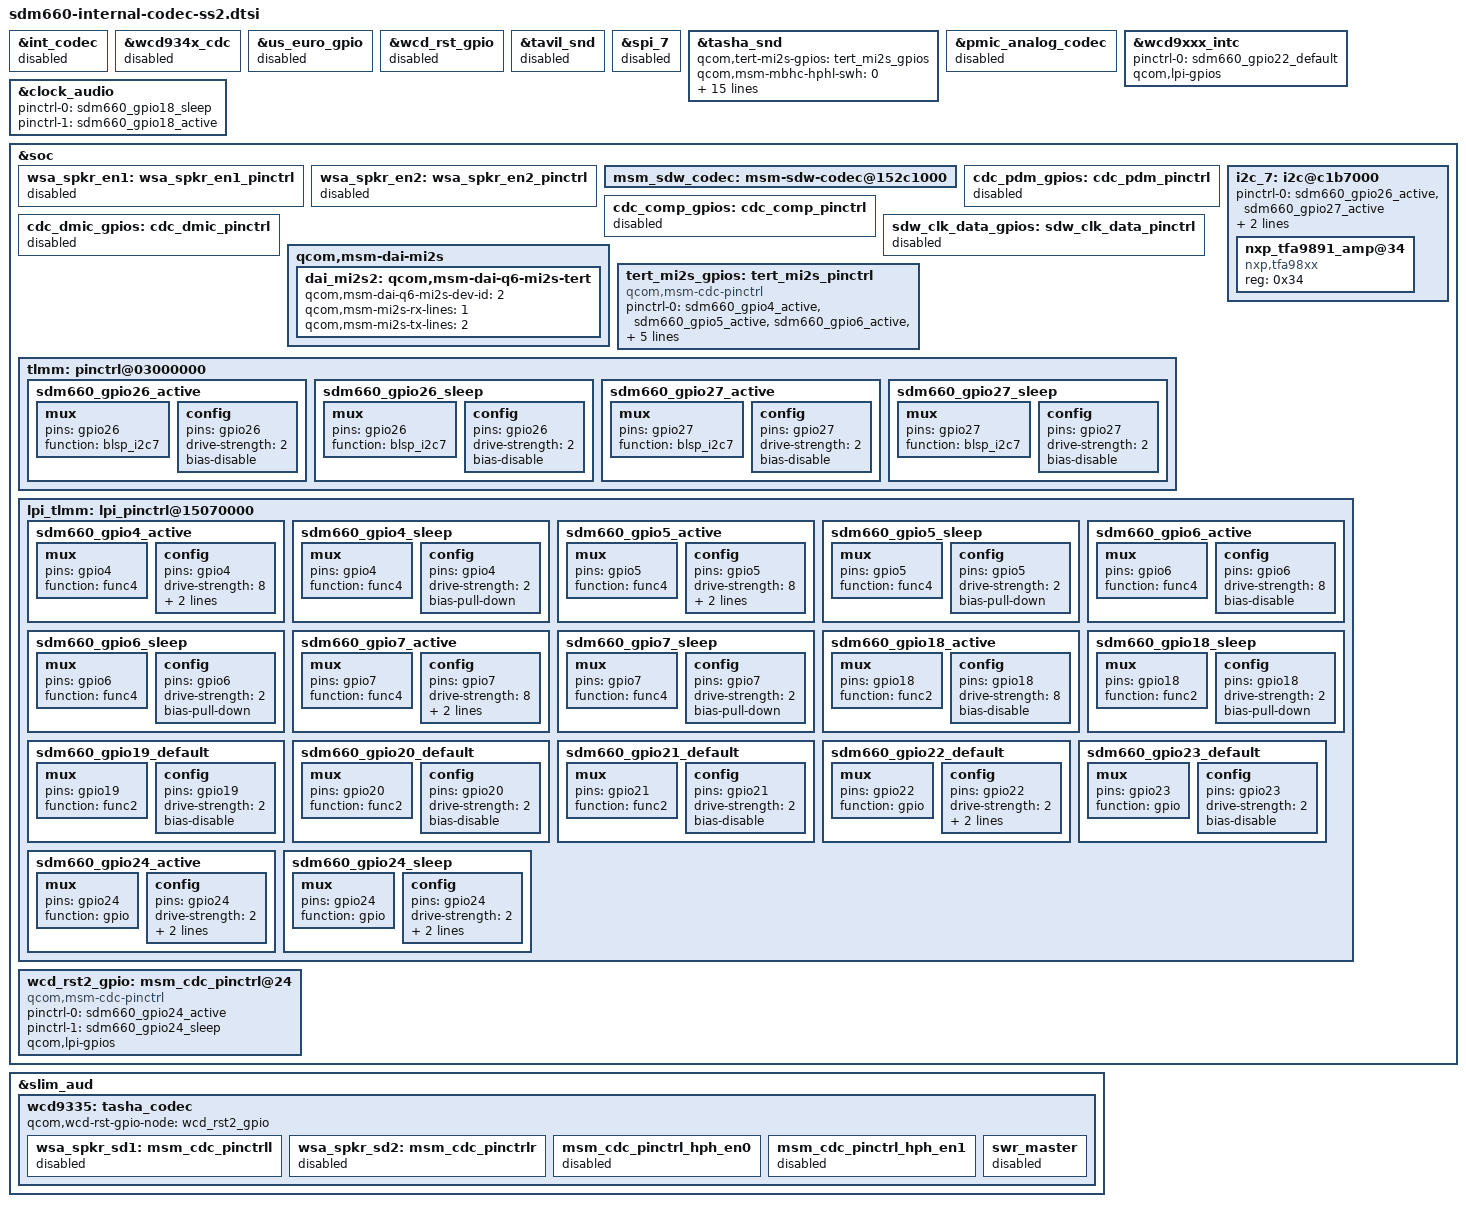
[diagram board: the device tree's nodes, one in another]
/* Copyright (c) 2017, The Linux Foundation. All rights reserved.
 *
 * This program is free software; you can redistribute it and/or modify
 * it under the terms of the GNU General Public License version 2 and
 * only version 2 as published by the Free Software Foundation.
 *
 * This program is distributed in the hope that it will be useful,
 * but WITHOUT ANY WARRANTY; without even the implied warranty of
 * MERCHANTABILITY or FITNESS FOR A PARTICULAR PURPOSE.  See the
 * GNU General Public License for more details.
 */


&int_codec {
  status = "disabled";
};

&wcd934x_cdc {
  status = "disabled";
};

&us_euro_gpio {
  status = "disabled";
};

&wcd_rst_gpio {
  status = "disabled";
};


&tavil_snd {
  status = "disabled";
};

&spi_7 {
  status = "disabled";
};

//&wdsp_mgr {
//  status = "disabled";
//};

//&wdsp_glink {
//  status = "disabled";
//};

//&glink_spi_xprt_wdsp {
//  status = "disabled";
//};

//&glink_fifo_wdsp {
//  status = "disabled";
//};

//&glink_qos_wdsp {
//  status = "disabled";
//};

&tasha_snd {

  qcom,tert-mi2s-gpios = <&tert_mi2s_gpios>;
  /delete-property/ qcom,us-euro-gpios;
  /delete-property/ qcom,wsa-max-devs;
  /delete-property/ qcom,wsa-devs;
  /delete-property/ qcom,wsa-aux-dev-prefix;
  /delete-property/ qcom,hph-en0-gpio;
  /delete-property/ qcom,hph-en1-gpio;
	qcom,msm-mbhc-hphl-swh = <0>;
	qcom,msm-mbhc-gnd-swh = <0>;
  qcom,audio-routing =
 "AIF4 VI", "MCLK", 
  "RX_BIAS", "MCLK", 
  "MADINPUT", "MCLK", 
  "AMIC2", "MIC BIAS2",
 "MIC BIAS2", "Analog Mic2", 
  "AMIC3", "MIC BIAS2", 
  "MIC BIAS2", "Analog Mic3", 
  "AMIC4", "MIC BIAS2", 
  "MIC BIAS2", "Analog Mic4", 
   "AMIC5", "MIC BIAS2", 
   "MIC BIAS2", "Analog Mic5", 
   "AMIC6", "MIC BIAS2", 
  "MIC BIAS2", "Analog Mic6", 
  "DMIC0", "MIC BIAS1",
   "MIC BIAS1", "Digital Mic0", 
  "DMIC1", "MIC BIAS1",
 "MIC BIAS1", "Handset Mic",
 "DMIC2", "MIC BIAS3",
 "MIC BIAS3", "Digital Mic2",
 "DMIC3", "MIC BIAS3",
 "MIC BIAS3", "Secondary Mic",
 "DMIC4", "MIC BIAS4",
 "MIC BIAS4", "Digital Mic4",
 "DMIC5", "MIC BIAS4",
 "MIC BIAS4", "Digital Mic5";
//  fih,nxp-tfa98xx;
  fih,ext-spk-amp-support;
};

&pmic_analog_codec {
  status = "disabled";
};

&msm_sdw_codec {
  status = "okay";
};

&wcd9xxx_intc {
  pinctrl-names = "default";
  pinctrl-0 = <&sdm660_gpio22_default>;
  qcom,lpi-gpios;
};

&clock_audio {
  pinctrl-0 =<&sdm660_gpio18_sleep>;
  pinctrl-1 =<&sdm660_gpio18_active>;
};

&soc{

    wsa_spkr_en1: wsa_spkr_en1_pinctrl {
        status = "disabled";
    };

    wsa_spkr_en2: wsa_spkr_en2_pinctrl {
        status = "disabled";
    };
//from ss2 dts
    msm_sdw_codec: msm-sdw-codec@152c1000 {
		status = "disabled";
     };
     cdc_pdm_gpios: cdc_pdm_pinctrl {
          status = "disabled";
	};

	cdc_comp_gpios: cdc_comp_pinctrl {
      status = "disabled";
	};

	cdc_dmic_gpios: cdc_dmic_pinctrl {
     status = "disabled";
	};
	sdw_clk_data_gpios: sdw_clk_data_pinctrl {
     status = "disabled";
	};
//from ss2 dts end
    /* TFA9891 SmartAmp I2S */
    qcom,msm-dai-mi2s {
        dai_mi2s2: qcom,msm-dai-q6-mi2s-tert {
            qcom,msm-dai-q6-mi2s-dev-id = <2>;
            qcom,msm-mi2s-rx-lines = <1>;
            qcom,msm-mi2s-tx-lines = <2>;
        };
    };
    tert_mi2s_gpios: tert_mi2s_pinctrl {
		compatible = "qcom,msm-cdc-pinctrl";
		pinctrl-names = "aud_active", "aud_sleep";
		pinctrl-0 = <&sdm660_gpio4_active &sdm660_gpio5_active &sdm660_gpio6_active &sdm660_gpio7_active>;
		pinctrl-1 = <&sdm660_gpio4_sleep &sdm660_gpio5_sleep &sdm660_gpio6_sleep &sdm660_gpio7_sleep>;
		qcom,lpi-gpios;
    };
    /* TFA9891 SmartAmp I2C */
    i2c_7: i2c@c1b7000 {
            pinctrl-names = "i2c_active", "i2c_sleep";
            pinctrl-0 = <&sdm660_gpio26_active &sdm660_gpio27_active>;
            pinctrl-1 = <&sdm660_gpio26_sleep &sdm660_gpio27_sleep>;
            status = "okay";
            nxp_tfa9891_amp@34 {
                compatible = "nxp,tfa98xx";
                reg = <0x34>;
		};

    };
    
    /* gpio */
	tlmm: pinctrl@03000000 {
		/* gpio 26 */ /* SPK_I2C_SDA */
		sdm660_gpio26_active: sdm660_gpio26_active {
			mux {
				pins = "gpio26";
				function = "blsp_i2c7";
			};

			config {
				pins = "gpio26";
				drive-strength = <2>;
				bias-disable;
			};
		};

		sdm660_gpio26_sleep: sdm660_gpio26_sleep {
			mux {
				pins = "gpio26";
				function = "blsp_i2c7";
			};

			config {
				pins = "gpio26";
				drive-strength = <2>;
				bias-disable;
			};
		};

		/* gpio 27 */ /* SPK_I2C_SCL */
		sdm660_gpio27_active: sdm660_gpio27_active {
			mux {
				pins = "gpio27";
				function = "blsp_i2c7";
			};

			config {
				pins = "gpio27";
				drive-strength = <2>;
				bias-disable;
			};
		};

		sdm660_gpio27_sleep: sdm660_gpio27_sleep {
			mux {
				pins = "gpio27";
				function = "blsp_i2c7";
			};

			config {
				pins = "gpio27";
				drive-strength = <2>;
				bias-disable;
			};
		};
    };
        /* gpio */
    lpi_tlmm: lpi_pinctrl@15070000 {
        /* gpio 4 */ /* SPK_I2S_CLK */
        sdm660_gpio4_active: sdm660_gpio4_active {
            mux {
                pins = "gpio4";
                function = "func4";
            };

            config {
                pins = "gpio4";
                drive-strength = <8>;
                bias-disable;
                output-high;
            };
        };

        sdm660_gpio4_sleep: sdm660_gpio4_sleep {
            mux {
                pins = "gpio4";
                function = "func4";
            };

            config {
                pins = "gpio4";
                drive-strength = <2>;
                bias-pull-down;
            };
        };

        /* gpio 5 */ /* SPK_I2S_WS */
        sdm660_gpio5_active: sdm660_gpio5_active {
            mux {
                pins = "gpio5";
                function = "func4";
            };

            config {
                pins = "gpio5";
                drive-strength = <8>;
                bias-disable;
                output-high;
            };
        };

        sdm660_gpio5_sleep: sdm660_gpio5_sleep {
            mux {
                pins = "gpio5";
                function = "func4";
            };

            config {
                pins = "gpio5";
                drive-strength = <2>;
                bias-pull-down;
            };
        };

        /* gpio 6 */ /* SPK_I2S_DATA0 */
        sdm660_gpio6_active: sdm660_gpio6_active {
            mux {
                pins = "gpio6";
                function = "func4";
            };

            config {
                pins = "gpio6";
                drive-strength = <8>;
                bias-disable;
            };
        };

        sdm660_gpio6_sleep: sdm660_gpio6_sleep {
            mux {
                pins = "gpio6";
                function = "func4";
            };

            config {
                pins = "gpio6";
                drive-strength = <2>;
                bias-pull-down;
            };
        };

        /* gpio 7 */ /* SPK_I2S_DATA1 */
        sdm660_gpio7_active: sdm660_gpio7_active {
            mux {
                pins = "gpio7";
                function = "func4";
            };

            config {
                pins = "gpio7";
                drive-strength = <8>;
                bias-disable;
                input-enable;
            };
        };

        sdm660_gpio7_sleep: sdm660_gpio7_sleep {
            mux {
                pins = "gpio7";
                function = "func4";
            };

            config {
                pins = "gpio7";
                drive-strength = <2>;
                bias-pull-down;
            };
        };
			sdm660_gpio18_active: sdm660_gpio18_active {
			
				mux {
					pins = "gpio18";
					function = "func2";
				};

				config {
					pins = "gpio18";
					drive-strength = <8>;
					bias-disable;
				};
			};

			sdm660_gpio18_sleep: sdm660_gpio18_sleep {

				mux {
					pins = "gpio18";
					function = "func2";
				};

				config {
					pins = "gpio18";
					drive-strength = <2>;
					bias-pull-down;
				};
			};

			sdm660_gpio19_default: sdm660_gpio19_default {

				mux {
					pins = "gpio19";
					function = "func2";
				};

				config {
					pins = "gpio19";
					drive-strength = <2>;
					bias-disable;
				};
			};

			sdm660_gpio20_default: sdm660_gpio20_default {

				mux {
					pins = "gpio20";
					function = "func2";
				};

				config {
					pins = "gpio20";
					drive-strength = <2>;
					bias-disable;
				};
			};

			sdm660_gpio21_default: sdm660_gpio21_default {

				mux {
					pins = "gpio21";
					function = "func2";
				};

				config {
					pins = "gpio21";
					drive-strength = <2>;
					bias-disable;
				};
			};

			sdm660_gpio22_default: sdm660_gpio22_default {

				mux {
					pins = "gpio22";
					function = "gpio";
				};

				config {
					pins = "gpio22";
					drive-strength = <2>;
					bias-disable;
					input-enable;
				};
			};

			sdm660_gpio23_default: sdm660_gpio23_default {

				mux {
					pins = "gpio23";
					function = "gpio";
				};

				config {
					pins = "gpio23";
					drive-strength = <2>;
					bias-disable;
				};
			};

			sdm660_gpio24_active: sdm660_gpio24_active {

				mux {
					pins = "gpio24";
					function = "gpio";
				};

				config {
					pins = "gpio24";
					drive-strength = <2>;
					bias-disable;
					output-high;
				};
			};

			sdm660_gpio24_sleep: sdm660_gpio24_sleep {

				mux {
					pins = "gpio24";
					function = "gpio";
				};

				config {
					pins = "gpio24";
					drive-strength = <2>;
					bias-disable;
					output-low;
				};
			};
    };
};
// from dts SS2

&slim_aud {
	wcd9335: tasha_codec {
                qcom,wcd-rst-gpio-node = <&wcd_rst2_gpio>;

		wsa_spkr_sd1: msm_cdc_pinctrll {
		status = "disabled";
		};

		wsa_spkr_sd2: msm_cdc_pinctrlr {
		status = "disabled";
		};
                msm_cdc_pinctrl_hph_en0 {
		status = "disabled";
		};
                msm_cdc_pinctrl_hph_en1 {
		status = "disabled";
		};
                swr_master {
		status = "disabled";
                };

	};
};

&soc {
             wcd_rst2_gpio: msm_cdc_pinctrl@24  {
		compatible = "qcom,msm-cdc-pinctrl";
		pinctrl-names = "aud_active", "aud_sleep";
		pinctrl-0 = <&sdm660_gpio24_active>;
		pinctrl-1 = <&sdm660_gpio24_sleep>;
		qcom,lpi-gpios;
                };
};



